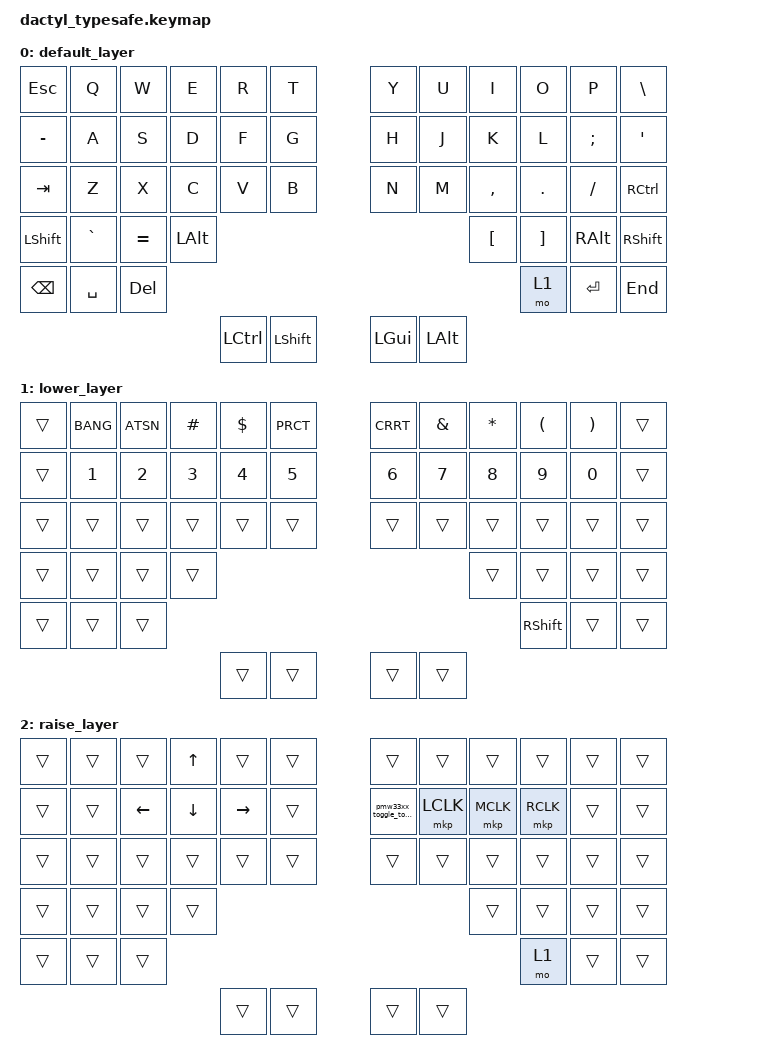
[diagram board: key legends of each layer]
/*
 * Copyright (c) 2020 The ZMK Contributors
 *
 * SPDX-License-Identifier: MIT
 */

#include <behaviors.dtsi>
#include <dt-bindings/zmk/keys.h>
#include <dt-bindings/zmk/mouse.h>
#include <dt-bindings/zmk/bt.h>
#include <dt-bindings/zmk/pmw33xx.h>

/ {
	keymap {
		compatible = "zmk,keymap";

		default_layer {
			bindings = <
&kp ESC   &kp Q     &kp W     &kp E     &kp R     &kp T                        &kp Y      &kp U     &kp I     &kp O     &kp P     &kp BSLH
&kp MINUS &kp A     &kp S     &kp D     &kp F     &kp G                        &kp H      &kp J     &kp K     &kp L     &kp SEMI  &kp SQT
&kp TAB   &kp Z     &kp X     &kp C     &kp V     &kp B                        &kp N      &kp M     &kp COMMA &kp DOT   &kp FSLH  &kp RCTRL
&kp LSHFT &kp GRAVE &kp EQUAL &kp LALT                                                              &kp LBKT  &kp RBKT  &kp RALT  &kp RSHFT
										&kp BSPC  &kp SPACE &kp DEL     &mo 1 0  &kp ENTER  &kp END
&kp LCTRL &kp LSHIFT &kp LGUI &kp LALT
			>;
		};

		lower_layer {
			bindings = <
&trans    &kp BANG  &kp ATSN  &kp HASH  &kp DLLR  &kp PRCT                      &kp CRRT &kp AMPS  &kp STAR  &kp LPAR  &kp RPAR  &trans
&trans    &kp N1    &kp N2    &kp N3    &kp N4    &kp N5                        &kp N6   &kp N7    &kp N8    &kp N9    &kp N0    &trans
&trans    &trans    &trans    &trans    &trans    &trans                        &trans   &trans    &trans    &trans    &trans    &trans
&trans    &trans    &trans    &trans                                                               &trans    &trans    &trans    &trans
										&trans    &trans   &trans    &kp RSHFT  &trans   &trans
&trans &trans &trans &trans
			>;
		};

		raise_layer {
			bindings = <
&trans    &trans    &trans    &kp UP    &trans    &trans                        &trans                  &trans    &trans    &trans    &trans   &trans
&trans    &trans    &kp LEFT  &kp DOWN  &kp RIGHT &trans                        &pmw33xx_toggle_toggle  &mkp LCLK &mkp MCLK &mkp RCLK &trans    &trans
&trans    &trans    &trans    &trans    &trans    &trans                        &trans                  &trans    &trans    &trans    &trans    &trans
&trans    &trans    &trans    &trans                                                                    &trans    &trans    &trans    &trans
										&trans    &trans   &trans    &mo 1 0  &trans   &trans
&trans &trans &trans &trans
			>;
		};
	};
};
